# PIC32MK1024GPK100 device description
Architecture: MIPS; Family: PIC32MK; Series: PIC32MK
Registers are 32-bit, read-write, no defined reset value unless marked. A register's access mark holds for its fields unless they carry their own. Offsets are from the block's base; [hi:lo] are bit positions; {n}, {i} and the like mark numbered series.

## EEPROM
Instances: EEPROM 0x1f829000 in periph_pb2_std
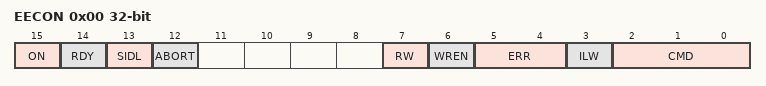
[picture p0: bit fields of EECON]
0x00 EECON — EEPROM Control Register
  [15] ON — Data EEPROM Power Control bit
    1=Data EEPROM is enabled; 0=Data EEPROM is disabled
  [14] RDY — Data EEPROM Ready bit
    1=Data EEPROM is ready for access; 0=Data EEPROM is not ready for access
  [13] SIDL — Stop in Idle Mode bit
    1=Discontinue operation when CPU enters in Idle mode; 0=Continue operation in Idle mode
  [12] ABORT — Data EEPROM Abort Operation Control bit
    1=Set by software to abort the on-going write command as soon as possible; 0=Data EEPROM panel is ready/Normal operation
  [7] RW — Start Command Execution Control bit
    1=(When WREN is 1)Start memory word program or erase command / (When WREN is 0)Start memory word read command; 0=(When WREN is 1)Cleared by hardware to indicate program or erase operation has completed / (When WREN is 0)Cleared by hardware to indicate read operation has completed
  [6] WREN — Data EEPROM Write Enable Control bit
    1=Enables program or erase operations; 0=Disables program or erase of memory elements, and enables read operations
  [5:4] ERR — Data EEPROM Sequence Error Status bits
    3=A BOR event has occurred; 2=An attempted execution of a read or write operation with an invalid write OR command with a misaligned address; 1=A Bulk or Page Erase or a Word Program verify error has occurred; 0=No error condition
  [3] ILW — Data EEPROM Imminent Long Write Status bit
    1=The next write to the EEPROM address (held in the EEADDR register) will require more time (~ 20 ms) than usual; 0=The next write to the EEPROM address (held in the EEADDR register) will be a normal write cycle
  [2:0] CMD — Data EEPROM Command Selection bits
    4=Configuration register Write command (WREN bit must be set); 3=Data EEPROM memory Bulk Erase command (WREN bit must be set); 2=Data EEPROM memory Page Erase command (WREN bit must be set); 1=Word Write command (WREN bit must be set); 0=Word Read command (WREN bit must be clear)
0x10 EEKEY wo
  [15:0] EEKEY
0x20 EEADDR
  [13:0] EEADDR
0x30 EEDATA

## HLVD
Instances: HLVD 0x1f801800 in periph_pb1_std
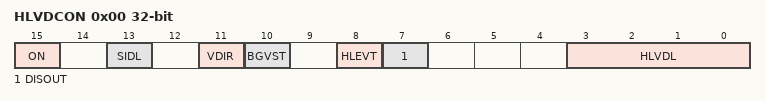
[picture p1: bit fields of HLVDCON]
0x00 HLVDCON — High/Low-Voltage Detect Control Register
  [15] ON — HLVD Module Enable bit
    1=HLVD module is enabled; 0=HLVD module is disabled
  [13] SIDL — Stop in Idle Mode bit
    1=Discontinue operation of LVD when device enters Idle mode; 0=Continue operation of LVD in Idle mode
  [11] VDIR — Voltage Change Direction Select bit
    1=Event occurs when voltage equals or exceeds the trip point (HLVDL); 0=Event occurs when voltage equals or falls below the trip point (HLVDL)
  [10] BGVST — Band Gap Reference Voltages Stable Status bit
    1=Indicates internal band gap voltage references is stable; 0=Indicates internal band gap voltage reference is not stable
  [8] HLEVT — High/Low-Voltage Detection Event Status bit
    1=Indicates HLVD Event is active; 0=Indicates HLVD Event is not active
  [7] DISOUT — Disable HLVD Output bit
    1=Enable output of HLVD Comparator. Once set, can only be cleared by setting the ON bit to 0.; 0=Disable output of HLVD Comparator (default Reset value)
  [3:0] HLVDL — High/Low-Voltage Detection Limit Select bits
    15=1.2V (Selects external LVDIN pin); 14=2.00V; 13=2.12V; 12=2.20V; 11=2.30V; 10=2.4V; 9=2.5V; 8=2.7V; 7=2.79V; 6=3.0V; 5=3.29V; 4=3.52V

## ICAP
Instances: ICAP 0x1f820000 in periph_pb2_std
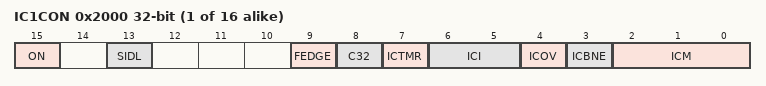
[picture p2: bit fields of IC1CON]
{0x1E00+0x200*i} IC{i}CON (i=1..16) — Input Capture x Control Register
  [15] ON — Input Capture Module Enable bit
    1=Module is enabled; 0=Disable and reset module
  [13] SIDL — Stop in Idle Control bit
    1=Halt in CPU Idle mode; 0=Continue to operate in CPU Idle mode
  [9] FEDGE — First Capture Edge Select bit
    1=Capture rising edge first; 0=Capture falling edge first
  [8] C32 — 32-bit Capture Select bit
    1=32-bit timer resource capture; 0=16-bit timer resource capture
  [7] ICTMR — Timer Select bit
    0=Timery is the counter source for capture; 1=Timerx is the counter source for capture
  [6:5] ICI — Interrupt Control bits
    3=Interrupt on every fourth capture event; 2=Interrupt on every third capture event; 1=Interrupt on every second capture event; 0=Interrupt on every capture event
  [4] ICOV — Input Capture Overflow Status Flag bit
    1=Input capture overflow is occurred; 0=No input capture overflow is occurred
  [3] ICBNE — Input Capture Buffer Not Empty Status bit
    1=Input capture buffer is not empty; at least one more capture value can be read; 0=Input capture buffer is empty
  [2:0] ICM — Input Capture Mode Select bits
    7=Interrupt-Only mode (only supported while in Sleep mode or Idle mode); 6=Simple Capture Event mode every edge; 5=Prescaled Capture Event mode every sixteenth rising edge; 4=Prescaled Capture Event mode every fourth rising edge; 3=Simple Capture Event mode every rising edge; 2=Simple Capture Event mode every falling edge; 1=Edge Detect mode every edge (rising and falling); 0=Input Capture module is disabled
{0x1E10+0x200*i} IC{i}BUF ro (i=1..16)

## Notices in the file
Copyright (c) 2019 Microchip Technology Inc.
SPDX-License-Identifier: Apache-2.0
Licensed under the Apache License, Version 2.0 (the "License");
you may not use this file except in compliance with the License.
You may obtain a copy of the License at
http://www.apache.org/licenses/LICENSE-2.0
Unless required by applicable law or agreed to in writing, software
distributed under the License is distributed on an "AS IS" BASIS,
WITHOUT WARRANTIES OR CONDITIONS OF ANY KIND, either express or implied.
See the License for the specific language governing permissions and
limitations under the License.
